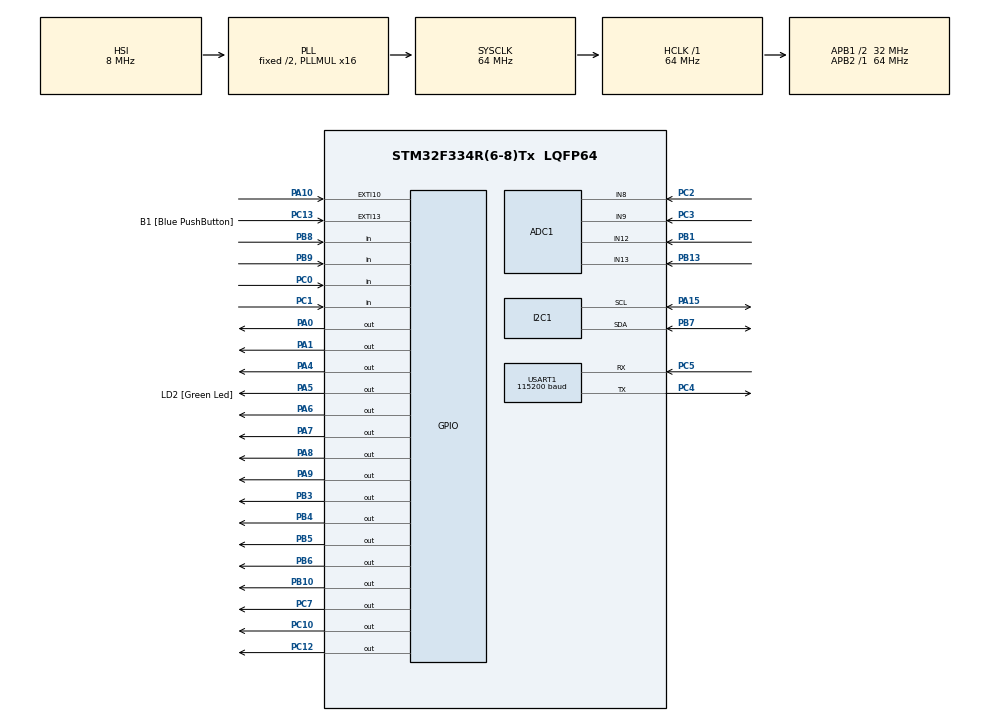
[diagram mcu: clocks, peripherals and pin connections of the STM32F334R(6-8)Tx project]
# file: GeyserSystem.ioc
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ADC1.Channel-0\#ChannelRegularConversion=ADC_CHANNEL_9
ADC1.NbrOfConversionFlag=1
ADC1.Offset-0\#ChannelRegularConversion=0
ADC1.OffsetNumber-0\#ChannelRegularConversion=ADC_OFFSET_NONE
ADC1.Rank-0\#ChannelRegularConversion=1
ADC1.SamplingTime-0\#ChannelRegularConversion=ADC_SAMPLETIME_1CYCLE_5
ADC1.SubFamily=STM32F334x8
ADC1.master=1
Mcu.Family=STM32F3
Mcu.Name=STM32F334R(6-8)Tx
Mcu.Package=LQFP64
NVIC.EXTI15_10_IRQn=true\:0\:0\:false\:false\:true\:true
NVIC.I2C1_ER_IRQn=true\:0\:0\:false\:false\:true\:true
NVIC.I2C1_EV_IRQn=true\:0\:0\:false\:false\:true\:true
NVIC.PriorityGroup=NVIC_PRIORITYGROUP_0
NVIC.RTC_WKUP_IRQn=true\:0\:0\:false\:false\:true\:true
NVIC.TIM2_IRQn=true\:0\:0\:false\:false\:true\:true
NVIC.USART1_IRQn=true\:0\:0\:false\:false\:true\:true
PA0.GPIO_ModeDefaultOutputPP=GPIO_MODE_OUTPUT_OD
PA0.GPIO_PuPd=GPIO_PULLUP
PA0.PinState=GPIO_PIN_SET
PA0.Signal=GPIO_Output
PA1.GPIO_ModeDefaultOutputPP=GPIO_MODE_OUTPUT_OD
PA1.GPIO_PuPd=GPIO_PULLUP
PA1.PinState=GPIO_PIN_SET
PA1.Signal=GPIO_Output
PA10.GPIO_ModeDefaultEXTI=GPIO_MODE_IT_RISING_FALLING
PA10.Signal=GPXTI10
PA13.GPIO_Label=TMS
PA13.Signal=SYS_JTMS-SWDIO
PA14.GPIO_Label=TCK
PA14.Signal=SYS_JTCK-SWCLK
PA15.Mode=I2C
PA15.Signal=I2C1_SCL
PA2.GPIO_Label=USART_TX
PA2.Signal=USART2_TX
PA3.GPIO_Label=USART_RX
PA3.Signal=USART2_RX
PA4.GPIO_ModeDefaultOutputPP=GPIO_MODE_OUTPUT_OD
PA4.GPIO_PuPd=GPIO_PULLUP
PA4.PinState=GPIO_PIN_SET
PA4.Signal=GPIO_Output
PA5.GPIO_Label=LD2 [Green Led]
PA5.Signal=GPIO_Output
PA6.Signal=GPIO_Output
PA7.Signal=GPIO_Output
PA8.Signal=GPIO_Output
PA9.Signal=GPIO_Output
PB1.Mode=IN12-Single-Ended
PB1.Signal=ADC1_IN12
PB10.Signal=GPIO_Output
PB13.Mode=IN13-Single-Ended
PB13.Signal=ADC1_IN13
PB3.Signal=GPIO_Output
PB4.Signal=GPIO_Output
PB5.Signal=GPIO_Output
PB6.Signal=GPIO_Output
PB7.Mode=I2C
PB7.Signal=I2C1_SDA
PB8.Signal=GPIO_Input
PB9.Signal=GPIO_Input
PC0.Signal=GPIO_Input
PC1.Signal=GPIO_Input
PC10.Signal=GPIO_Output
PC12.Signal=GPIO_Output
PC13.GPIO_Label=B1 [Blue PushButton]
PC13.GPIO_ModeDefaultEXTI=GPIO_MODE_IT_FALLING
PC13.Signal=GPXTI13
PC14\ /\ OSC32_IN.Mode=LSE-External-Oscillator
PC14\ /\ OSC32_IN.Signal=RCC_OSC32_IN
PC15\ /\ OSC32_OUT.GPIO_Label=RCC_OSC32_OUT
PC15\ /\ OSC32_OUT.Mode=LSE-External-Oscillator
PC15\ /\ OSC32_OUT.Signal=RCC_OSC32_OUT
PC2.Signal=ADCx_IN8
PC3.Signal=ADCx_IN9
PC4.GPIO_PuPd=GPIO_PULLUP
PC4.Mode=Asynchronous
PC4.Signal=USART1_TX
PC5.GPIO_PuPd=GPIO_PULLUP
PC5.Mode=Asynchronous
PC5.Signal=USART1_RX
PC7.Signal=GPIO_Output
PF0\ /\ OSC_IN.Signal=RCC_OSC_IN
PF1\ /\ OSC_OUT.Signal=RCC_OSC_OUT
ProjectManager.HeapSize=0x200
ProjectManager.StackSize=0x400
ProjectManager.TargetToolchain=TrueSTUDIO
RCC.AHBFreq_Value=64000000
RCC.APB1CLKDivider=RCC_HCLK_DIV2
RCC.APB1Freq_Value=32000000
RCC.APB1TimFreq_Value=64000000
RCC.APB2Freq_Value=64000000
RCC.APB2TimFreq_Value=64000000
RCC.CortexFreq_Value=64000000
RCC.FLatency-AdvancedSettings=FLASH_LATENCY_2
RCC.HCLKFreq_Value=64000000
RCC.HSE_VALUE=8000000
RCC.HSI_VALUE=8000000
RCC.PLLMUL=RCC_PLL_MUL16
RCC.RTCClockSelection=RCC_RTCCLKSOURCE_LSE
RCC.SYSCLKFreq_VALUE=64000000
RCC.SYSCLKSourceVirtual=RCC_SYSCLKSOURCE_PLLCLK
RTC.WakeUpClock-WakeUp=RTC_WAKEUPCLOCK_CK_SPRE_16BITS
SH.ADCx_IN8.0=ADC1_IN8,IN8-Single-Ended
SH.ADCx_IN9.0=ADC1_IN9,IN9-Single-Ended
TIM2.AutoReloadPreload=TIM_AUTORELOAD_PRELOAD_ENABLE
TIM2.CounterMode=TIM_COUNTERMODE_DOWN
TIM2.Period=16000
USART1.BaudRate=115200
USART1.VirtualMode-Asynchronous=VM_ASYNC
USART1.WordLength=WORDLENGTH_8B
VP_RTC_VS_RTC_Activate.Mode=RTC_Enabled
VP_RTC_VS_RTC_Calendar.Mode=RTC_Calendar
VP_RTC_VS_RTC_WakeUp_intern.Mode=WakeUp
VP_TIM2_VS_ClockSourceINT.Mode=Internal
VP_TIM7_VS_ClockSourceINT.Mode=Enable_Timer
board=NUCLEO-F334R8

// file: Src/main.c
/**
  ******************************************************************************
  * @file           : main.c
  * @brief          : Main program body
  ******************************************************************************
  ** This notice applies to any and all portions of this file
  * that are not between comment pairs USER CODE BEGIN and
  * USER CODE END. Other portions of this file, whether
  * inserted by the user or by software development tools
  * are owned by their respective copyright owners.
  *
  * COPYRIGHT(c) 2018 STMicroelectronics
  *
  * Redistribution and use in source and binary forms, with or without modification,
  * are permitted provided that the following conditions are met:
  *   1. Redistributions of source code must retain the above copyright notice,
  *      this list of conditions and the following disclaimer.
  *   2. Redistributions in binary form must reproduce the above copyright notice,
  *      this list of conditions and the following disclaimer in the documentation
  *      and/or other materials provided with the distribution.
  *   3. Neither the name of STMicroelectronics nor the names of its contributors
  *      may be used to endorse or promote products derived from this software
  *      without specific prior written permission.
  *
  * THIS SOFTWARE IS PROVIDED BY THE COPYRIGHT HOLDERS AND CONTRIBUTORS "AS IS"
  * AND ANY EXPRESS OR IMPLIED WARRANTIES, INCLUDING, BUT NOT LIMITED TO, THE
  * IMPLIED WARRANTIES OF MERCHANTABILITY AND FITNESS FOR A PARTICULAR PURPOSE ARE
  * DISCLAIMED. IN NO EVENT SHALL THE COPYRIGHT HOLDER OR CONTRIBUTORS BE LIABLE
  * FOR ANY DIRECT, INDIRECT, INCIDENTAL, SPECIAL, EXEMPLARY, OR CONSEQUENTIAL
  * DAMAGES (INCLUDING, BUT NOT LIMITED TO, PROCUREMENT OF SUBSTITUTE GOODS OR
  * SERVICES; LOSS OF USE, DATA, OR PROFITS; OR BUSINESS INTERRUPTION) HOWEVER
  * CAUSED AND ON ANY THEORY OF LIABILITY, WHETHER IN CONTRACT, STRICT LIABILITY,
  * OR TORT (INCLUDING NEGLIGENCE OR OTHERWISE) ARISING IN ANY WAY OUT OF THE USE
  * OF THIS SOFTWARE, EVEN IF ADVISED OF THE POSSIBILITY OF SUCH DAMAGE.
  *
  ******************************************************************************
  */
#include "main.h"
#include "stm32f3xx_hal.h"

/* USER CODE BEGIN Includes */
#include "user.h"
#include "main.h"
/* USER CODE END Includes */

ADC_HandleTypeDef hadc1;

I2C_HandleTypeDef hi2c1;

RTC_HandleTypeDef hrtc;

TIM_HandleTypeDef htim2;
TIM_HandleTypeDef htim7;

UART_HandleTypeDef huart1;

/* USER CODE BEGIN PV */
/* Private variables ---------------------------------------------------------*/

/* USER CODE END PV */

void SystemClock_Config(void);
static void MX_GPIO_Init(void);
static void MX_USART1_UART_Init(void);
static void MX_ADC1_Init(void);
static void MX_I2C1_Init(void);
static void MX_RTC_Init(void);
static void MX_TIM2_Init(void);
static void MX_TIM7_Init(void);

/* USER CODE BEGIN PFP */
/* Private function prototypes -----------------------------------------------*/

/* USER CODE END PFP */

int main(void)
{

  /* MCU Configuration----------------------------------------------------------*/

  /* Reset of all peripherals, Initializes the Flash interface and the Systick. */
  HAL_Init();

  /* Configure the system clock */
  SystemClock_Config();

  /* Initialize all configured peripherals */
  MX_GPIO_Init();
  MX_USART1_UART_Init();
  MX_ADC1_Init();
  MX_I2C1_Init();
  MX_RTC_Init();
  MX_TIM2_Init();
  MX_TIM7_Init();
  /* USER CODE BEGIN 2 */
  UserInitialise();
  /* USER CODE END 2 */

  /* Infinite loop */
  /* USER CODE BEGIN WHILE */
  while (1)
  {
	  Flags();
  /* USER CODE END WHILE */

  }

}

void SystemClock_Config(void)
{

  RCC_OscInitTypeDef RCC_OscInitStruct;
  RCC_ClkInitTypeDef RCC_ClkInitStruct;
  RCC_PeriphCLKInitTypeDef PeriphClkInit;

    /**Configure LSE Drive Capability
    */
  HAL_PWR_EnableBkUpAccess();

  __HAL_RCC_LSEDRIVE_CONFIG(RCC_LSEDRIVE_LOW);

    /**Initializes the CPU, AHB and APB busses clocks
    */
  RCC_OscInitStruct.OscillatorType = RCC_OSCILLATORTYPE_HSI|RCC_OSCILLATORTYPE_LSE;
  RCC_OscInitStruct.LSEState = RCC_LSE_ON;
  RCC_OscInitStruct.HSIState = RCC_HSI_ON;
  RCC_OscInitStruct.HSICalibrationValue = 16;
  RCC_OscInitStruct.PLL.PLLState = RCC_PLL_ON;
  RCC_OscInitStruct.PLL.PLLSource = RCC_PLLSOURCE_HSI;
  RCC_OscInitStruct.PLL.PLLMUL = RCC_PLL_MUL16;
  if (HAL_RCC_OscConfig(&RCC_OscInitStruct) != HAL_OK)
  {
    _Error_Handler(__FILE__, __LINE__);
  }

    /**Initializes the CPU, AHB and APB busses clocks
    */
  RCC_ClkInitStruct.ClockType = RCC_CLOCKTYPE_HCLK|RCC_CLOCKTYPE_SYSCLK
                              |RCC_CLOCKTYPE_PCLK1|RCC_CLOCKTYPE_PCLK2;
  RCC_ClkInitStruct.SYSCLKSource = RCC_SYSCLKSOURCE_PLLCLK;
  RCC_ClkInitStruct.AHBCLKDivider = RCC_SYSCLK_DIV1;
  RCC_ClkInitStruct.APB1CLKDivider = RCC_HCLK_DIV2;
  RCC_ClkInitStruct.APB2CLKDivider = RCC_HCLK_DIV1;

  if (HAL_RCC_ClockConfig(&RCC_ClkInitStruct, FLASH_LATENCY_2) != HAL_OK)
  {
    _Error_Handler(__FILE__, __LINE__);
  }

  PeriphClkInit.PeriphClockSelection = RCC_PERIPHCLK_USART1|RCC_PERIPHCLK_I2C1
                              |RCC_PERIPHCLK_RTC|RCC_PERIPHCLK_ADC12;
  PeriphClkInit.Usart1ClockSelection = RCC_USART1CLKSOURCE_PCLK1;
  PeriphClkInit.Adc12ClockSelection = RCC_ADC12PLLCLK_DIV1;
  PeriphClkInit.I2c1ClockSelection = RCC_I2C1CLKSOURCE_HSI;
  PeriphClkInit.RTCClockSelection = RCC_RTCCLKSOURCE_LSE;
  if (HAL_RCCEx_PeriphCLKConfig(&PeriphClkInit) != HAL_OK)
  {
    _Error_Handler(__FILE__, __LINE__);
  }

    /**Configure the Systick interrupt time
    */
  HAL_SYSTICK_Config(HAL_RCC_GetHCLKFreq()/1000);

    /**Configure the Systick
    */
  HAL_SYSTICK_CLKSourceConfig(SYSTICK_CLKSOURCE_HCLK);

  /* SysTick_IRQn interrupt configuration */
  HAL_NVIC_SetPriority(SysTick_IRQn, 0, 0);
}

/* ADC1 init function */
static void MX_ADC1_Init(void)
{

  ADC_MultiModeTypeDef multimode;
  ADC_ChannelConfTypeDef sConfig;

    /**Common config
    */
  hadc1.Instance = ADC1;
  hadc1.Init.ClockPrescaler = ADC_CLOCK_ASYNC_DIV1;
  hadc1.Init.Resolution = ADC_RESOLUTION_12B;
  hadc1.Init.ScanConvMode = ADC_SCAN_DISABLE;
  hadc1.Init.ContinuousConvMode = DISABLE;
  hadc1.Init.DiscontinuousConvMode = DISABLE;
  hadc1.Init.ExternalTrigConvEdge = ADC_EXTERNALTRIGCONVEDGE_NONE;
  hadc1.Init.ExternalTrigConv = ADC_SOFTWARE_START;
  hadc1.Init.DataAlign = ADC_DATAALIGN_RIGHT;
  hadc1.Init.NbrOfConversion = 1;
  hadc1.Init.DMAContinuousRequests = DISABLE;
  hadc1.Init.EOCSelection = ADC_EOC_SINGLE_CONV;
  hadc1.Init.LowPowerAutoWait = DISABLE;
  hadc1.Init.Overrun = ADC_OVR_DATA_OVERWRITTEN;
  if (HAL_ADC_Init(&hadc1) != HAL_OK)
  {
    _Error_Handler(__FILE__, __LINE__);
  }

    /**Configure the ADC multi-mode
    */
  multimode.Mode = ADC_MODE_INDEPENDENT;
  if (HAL_ADCEx_MultiModeConfigChannel(&hadc1, &multimode) != HAL_OK)
  {
    _Error_Handler(__FILE__, __LINE__);
  }

    /**Configure Regular Channel
    */
  sConfig.Channel = ADC_CHANNEL_9;
  sConfig.Rank = ADC_REGULAR_RANK_1;
  sConfig.SingleDiff = ADC_SINGLE_ENDED;
  sConfig.SamplingTime = ADC_SAMPLETIME_1CYCLE_5;
  sConfig.OffsetNumber = ADC_OFFSET_NONE;
  sConfig.Offset = 0;
  if (HAL_ADC_ConfigChannel(&hadc1, &sConfig) != HAL_OK)
  {
    _Error_Handler(__FILE__, __LINE__);
  }

}

/* I2C1 init function */
static void MX_I2C1_Init(void)
{

  hi2c1.Instance = I2C1;
  hi2c1.Init.Timing = 0x2000090E;
  hi2c1.Init.OwnAddress1 = 0;
  hi2c1.Init.AddressingMode = I2C_ADDRESSINGMODE_7BIT;
  hi2c1.Init.DualAddressMode = I2C_DUALADDRESS_DISABLE;
  hi2c1.Init.OwnAddress2 = 0;
  hi2c1.Init.OwnAddress2Masks = I2C_OA2_NOMASK;
  hi2c1.Init.GeneralCallMode = I2C_GENERALCALL_DISABLE;
  hi2c1.Init.NoStretchMode = I2C_NOSTRETCH_DISABLE;
  if (HAL_I2C_Init(&hi2c1) != HAL_OK)
  {
    _Error_Handler(__FILE__, __LINE__);
  }

    /**Configure Analogue filter
    */
  if (HAL_I2CEx_ConfigAnalogFilter(&hi2c1, I2C_ANALOGFILTER_ENABLE) != HAL_OK)
  {
    _Error_Handler(__FILE__, __LINE__);
  }

    /**Configure Digital filter
    */
  if (HAL_I2CEx_ConfigDigitalFilter(&hi2c1, 0) != HAL_OK)
  {
    _Error_Handler(__FILE__, __LINE__);
  }

}

/* RTC init function */
static void MX_RTC_Init(void)
{

  RTC_TimeTypeDef sTime;
  RTC_DateTypeDef sDate;

    /**Initialize RTC Only
    */
  hrtc.Instance = RTC;
if(HAL_RTCEx_BKUPRead(&hrtc, RTC_BKP_DR0) != 0x32F2){
  hrtc.Init.HourFormat = RTC_HOURFORMAT_24;
  hrtc.Init.AsynchPrediv = 127;
  hrtc.Init.SynchPrediv = 255;
  hrtc.Init.OutPut = RTC_OUTPUT_DISABLE;
  hrtc.Init.OutPutPolarity = RTC_OUTPUT_POLARITY_HIGH;
  hrtc.Init.OutPutType = RTC_OUTPUT_TYPE_OPENDRAIN;
  if (HAL_RTC_Init(&hrtc) != HAL_OK)
  {
    _Error_Handler(__FILE__, __LINE__);
  }

    /**Initialize RTC and set the Time and Date
    */
  sTime.Hours = 0x0;
  sTime.Minutes = 0x0;
  sTime.Seconds = 0x0;
  sTime.DayLightSaving = RTC_DAYLIGHTSAVING_NONE;
  sTime.StoreOperation = RTC_STOREOPERATION_RESET;
  if (HAL_RTC_SetTime(&hrtc, &sTime, RTC_FORMAT_BCD) != HAL_OK)
  {
    _Error_Handler(__FILE__, __LINE__);
  }

  sDate.WeekDay = RTC_WEEKDAY_MONDAY;
  sDate.Month = RTC_MONTH_JANUARY;
  sDate.Date = 0x1;
  sDate.Year = 0x0;

  if (HAL_RTC_SetDate(&hrtc, &sDate, RTC_FORMAT_BCD) != HAL_OK)
  {
    _Error_Handler(__FILE__, __LINE__);
  }

    /**Enable the WakeUp
    */
  if (HAL_RTCEx_SetWakeUpTimer_IT(&hrtc, 0, RTC_WAKEUPCLOCK_CK_SPRE_16BITS) != HAL_OK)
  {
    _Error_Handler(__FILE__, __LINE__);
  }

    HAL_RTCEx_BKUPWrite(&hrtc,RTC_BKP_DR0,0x32F2);
  }

}

/* TIM2 init function */
static void MX_TIM2_Init(void)
{

  TIM_ClockConfigTypeDef sClockSourceConfig;
  TIM_MasterConfigTypeDef sMasterConfig;

  htim2.Instance = TIM2;
  htim2.Init.Prescaler = 0;
  htim2.Init.CounterMode = TIM_COUNTERMODE_DOWN;
  htim2.Init.Period = 16000;
  htim2.Init.ClockDivision = TIM_CLOCKDIVISION_DIV1;
  htim2.Init.AutoReloadPreload = TIM_AUTORELOAD_PRELOAD_ENABLE;
  if (HAL_TIM_Base_Init(&htim2) != HAL_OK)
  {
    _Error_Handler(__FILE__, __LINE__);
  }

  sClockSourceConfig.ClockSource = TIM_CLOCKSOURCE_INTERNAL;
  if (HAL_TIM_ConfigClockSource(&htim2, &sClockSourceConfig) != HAL_OK)
  {
    _Error_Handler(__FILE__, __LINE__);
  }

  sMasterConfig.MasterOutputTrigger = TIM_TRGO_RESET;
  sMasterConfig.MasterSlaveMode = TIM_MASTERSLAVEMODE_DISABLE;
  if (HAL_TIMEx_MasterConfigSynchronization(&htim2, &sMasterConfig) != HAL_OK)
  {
    _Error_Handler(__FILE__, __LINE__);
  }

}

/* TIM7 init function */
static void MX_TIM7_Init(void)
{

  TIM_MasterConfigTypeDef sMasterConfig;

  htim7.Instance = TIM7;
  htim7.Init.Prescaler = 0;
  htim7.Init.CounterMode = TIM_COUNTERMODE_UP;
  htim7.Init.Period = 0;
  htim7.Init.AutoReloadPreload = TIM_AUTORELOAD_PRELOAD_DISABLE;
  if (HAL_TIM_Base_Init(&htim7) != HAL_OK)
  {
    _Error_Handler(__FILE__, __LINE__);
  }

  sMasterConfig.MasterOutputTrigger = TIM_TRGO_RESET;
  sMasterConfig.MasterSlaveMode = TIM_MASTERSLAVEMODE_DISABLE;
  if (HAL_TIMEx_MasterConfigSynchronization(&htim7, &sMasterConfig) != HAL_OK)
  {
    _Error_Handler(__FILE__, __LINE__);
  }

}

/* USART1 init function */
static void MX_USART1_UART_Init(void)
{

  huart1.Instance = USART1;
  huart1.Init.BaudRate = 115200;
  huart1.Init.WordLength = UART_WORDLENGTH_8B;
  huart1.Init.StopBits = UART_STOPBITS_1;
  huart1.Init.Parity = UART_PARITY_NONE;
  huart1.Init.Mode = UART_MODE_TX_RX;
  huart1.Init.HwFlowCtl = UART_HWCONTROL_NONE;
  huart1.Init.OverSampling = UART_OVERSAMPLING_16;
  huart1.Init.OneBitSampling = UART_ONE_BIT_SAMPLE_DISABLE;
  huart1.AdvancedInit.AdvFeatureInit = UART_ADVFEATURE_NO_INIT;
  if (HAL_UART_Init(&huart1) != HAL_OK)
  {
    _Error_Handler(__FILE__, __LINE__);
  }

}

/** Configure pins as
        * Analog
        * Input
        * Output
        * EVENT_OUT
        * EXTI
     PA2   ------> USART2_TX
     PA3   ------> USART2_RX
*/
static void MX_GPIO_Init(void)
{

  GPIO_InitTypeDef GPIO_InitStruct;

  /* GPIO Ports Clock Enable */
  __HAL_RCC_GPIOC_CLK_ENABLE();
  __HAL_RCC_GPIOF_CLK_ENABLE();
  __HAL_RCC_GPIOA_CLK_ENABLE();
  __HAL_RCC_GPIOB_CLK_ENABLE();

  /*Configure GPIO pin Output Level */
  HAL_GPIO_WritePin(GPIOA, GPIO_PIN_0|GPIO_PIN_1|GPIO_PIN_4, GPIO_PIN_SET);

  /*Configure GPIO pin Output Level */
  HAL_GPIO_WritePin(GPIOA, LD2_Pin|GPIO_PIN_6|GPIO_PIN_7|GPIO_PIN_8
                          |GPIO_PIN_9, GPIO_PIN_RESET);

  /*Configure GPIO pin Output Level */
  HAL_GPIO_WritePin(GPIOB, GPIO_PIN_10|GPIO_PIN_3|GPIO_PIN_4|GPIO_PIN_5
                          |GPIO_PIN_6, GPIO_PIN_RESET);

  /*Configure GPIO pin Output Level */
  HAL_GPIO_WritePin(GPIOC, GPIO_PIN_7|GPIO_PIN_10|GPIO_PIN_12, GPIO_PIN_RESET);

  /*Configure GPIO pin : B1_Pin */
  GPIO_InitStruct.Pin = B1_Pin;
  GPIO_InitStruct.Mode = GPIO_MODE_IT_FALLING;
  GPIO_InitStruct.Pull = GPIO_NOPULL;
  HAL_GPIO_Init(B1_GPIO_Port, &GPIO_InitStruct);

  /*Configure GPIO pins : PC0 PC1 */
  GPIO_InitStruct.Pin = GPIO_PIN_0|GPIO_PIN_1;
  GPIO_InitStruct.Mode = GPIO_MODE_INPUT;
  GPIO_InitStruct.Pull = GPIO_NOPULL;
  HAL_GPIO_Init(GPIOC, &GPIO_InitStruct);

  /*Configure GPIO pins : PA0 PA1 PA4 */
  GPIO_InitStruct.Pin = GPIO_PIN_0|GPIO_PIN_1|GPIO_PIN_4;
  GPIO_InitStruct.Mode = GPIO_MODE_OUTPUT_OD;
  GPIO_InitStruct.Pull = GPIO_PULLUP;
  GPIO_InitStruct.Speed = GPIO_SPEED_FREQ_LOW;
  HAL_GPIO_Init(GPIOA, &GPIO_InitStruct);

  /*Configure GPIO pins : USART_TX_Pin USART_RX_Pin */
  GPIO_InitStruct.Pin = USART_TX_Pin|USART_RX_Pin;
  GPIO_InitStruct.Mode = GPIO_MODE_AF_PP;
  GPIO_InitStruct.Pull = GPIO_NOPULL;
  GPIO_InitStruct.Speed = GPIO_SPEED_FREQ_HIGH;
  GPIO_InitStruct.Alternate = GPIO_AF7_USART2;
  HAL_GPIO_Init(GPIOA, &GPIO_InitStruct);

  /*Configure GPIO pins : LD2_Pin PA6 PA7 PA8
                           PA9 */
  GPIO_InitStruct.Pin = LD2_Pin|GPIO_PIN_6|GPIO_PIN_7|GPIO_PIN_8
                          |GPIO_PIN_9;
  GPIO_InitStruct.Mode = GPIO_MODE_OUTPUT_PP;
  GPIO_InitStruct.Pull = GPIO_NOPULL;
  GPIO_InitStruct.Speed = GPIO_SPEED_FREQ_LOW;
  HAL_GPIO_Init(GPIOA, &GPIO_InitStruct);

  /*Configure GPIO pins : PB10 PB3 PB4 PB5
                           PB6 */
  GPIO_InitStruct.Pin = GPIO_PIN_10|GPIO_PIN_3|GPIO_PIN_4|GPIO_PIN_5
                          |GPIO_PIN_6;
  GPIO_InitStruct.Mode = GPIO_MODE_OUTPUT_PP;
  GPIO_InitStruct.Pull = GPIO_NOPULL;
  GPIO_InitStruct.Speed = GPIO_SPEED_FREQ_LOW;
  HAL_GPIO_Init(GPIOB, &GPIO_InitStruct);

  /*Configure GPIO pins : PC7 PC10 PC12 */
  GPIO_InitStruct.Pin = GPIO_PIN_7|GPIO_PIN_10|GPIO_PIN_12;
  GPIO_InitStruct.Mode = GPIO_MODE_OUTPUT_PP;
  GPIO_InitStruct.Pull = GPIO_NOPULL;
  GPIO_InitStruct.Speed = GPIO_SPEED_FREQ_LOW;
  HAL_GPIO_Init(GPIOC, &GPIO_InitStruct);

  /*Configure GPIO pin : PA10 */
  GPIO_InitStruct.Pin = GPIO_PIN_10;
  GPIO_InitStruct.Mode = GPIO_MODE_IT_RISING_FALLING;
  GPIO_InitStruct.Pull = GPIO_NOPULL;
  HAL_GPIO_Init(GPIOA, &GPIO_InitStruct);

  /*Configure GPIO pins : PB8 PB9 */
  GPIO_InitStruct.Pin = GPIO_PIN_8|GPIO_PIN_9;
  GPIO_InitStruct.Mode = GPIO_MODE_INPUT;
  GPIO_InitStruct.Pull = GPIO_NOPULL;
  HAL_GPIO_Init(GPIOB, &GPIO_InitStruct);

  /* EXTI interrupt init*/
  HAL_NVIC_SetPriority(EXTI15_10_IRQn, 0, 0);
  HAL_NVIC_EnableIRQ(EXTI15_10_IRQn);

}

void _Error_Handler(char *file, int line)
{
  while(1)
  {
  }
}

/************************ (C) COPYRIGHT STMicroelectronics *****END OF FILE****/
